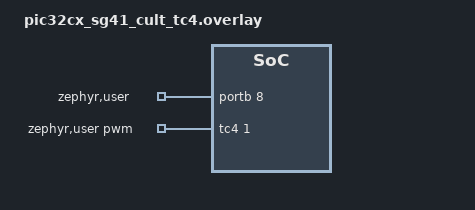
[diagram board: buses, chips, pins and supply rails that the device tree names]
/*
 * SPDX-FileCopyrightText: Copyright 2026 Microchip Technology Inc.
 * SPDX-License-Identifier: Apache-2.0
 */

/* connect PB09 to PB08 */

#define PWM_NODE    tc4
#define PWM_PINCTRL tc4_pwm_default
#include "mchp_pwm_loopback_support.dtsi"

/ {
	zephyr,user {
		pwms = <&tc4 1 PWM_MSEC(20) 0>;
		gpios = <&portb 8 GPIO_ACTIVE_HIGH>;
	};
};

&portb {
	status = "okay";
};

&pinctrl {
	tc4_pwm_default: tc4_pwm_default {
		group1 {
			pinmux = <PB9E_TC4_WO1>;
		};
	};
};
